# nrf9230_enga_sysctrl register map
Vendor: Nordic Semiconductor; Series: nRF92; File version: 1
Registers are 32-bit, read-write, reset 0x0 unless marked. A register's access mark holds for its fields unless they carry their own. Offsets are from the block's base; [hi:lo] are bit positions; lines under a group give offsets from that group; {n}, {i} and the like mark numbered series; 'fields as' and 'values as' point back to an identical list.

## ROMC — ROM Controller
Base 0x5F8C6000
0x500 POWER group — Unspecified
  0x00 CONTROL reset 0x1 — ROM power control register.
    [0] MEM0 — Keep the ROM block MEM[0] on or off when in System ON mode.
      0=Off (Power down); 1=On (Power up)

## MEMCONF120 — Memory configuration 0
Base 0x5F8C7000
Same registers: MEMCONF130 0x5F905000
{0x500+0x10*i} POWER[{i}] (i=0..1) group — Unspecified
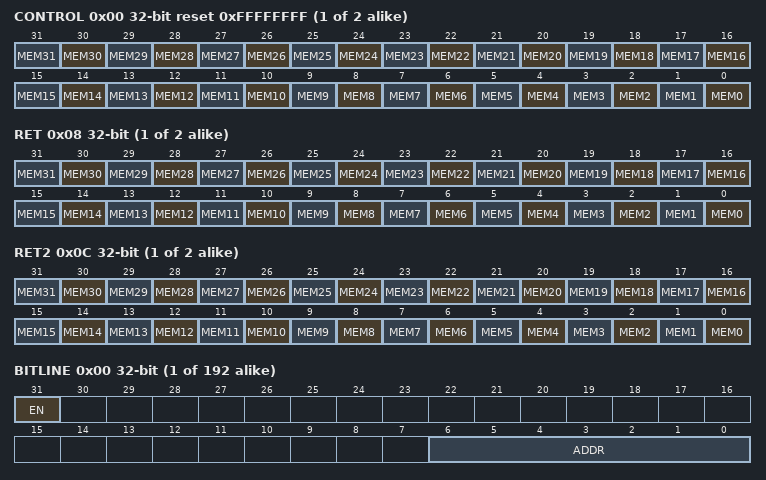
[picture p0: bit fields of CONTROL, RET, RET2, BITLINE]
  0x00 CONTROL reset 0xFFFFFFFF — Description cluster: Control memory block power.
    [all] fields
      0=Off (Power down); 1=On (Power up)
    [n] MEM{n} (n=0..31) — Keep the memory block MEM[{n}] on or off when in System ON mode.
  0x08 RET — Description cluster: RAM retention for RAM [n].
    [all] fields
      0=Off (Retention off); 1=On (Retention on)
    [n] MEM{n} (n=0..31) — Keep the RAM block MEM[{n}] retained when the parent power domain of the RAM is off.
  0x0C RET2 — Description cluster: RAM retention for the second bank in the RAM block
    [all] fields
      0=Off (Retention off); 1=On (Retention on)
    [n] MEM{n} (n=0..31) — Keep the second bank in RAM block MEM[{n}] retained when parent power domain of the RAM is off.
{0x600+4i} REPAIR[{i}] (i=0..191) group — Unspecified
  0x00 BITLINE — Description cluster: Repair configuration for RAM blocks.
    [31] EN — Enable bitline repair
      0=Disabled (Repair disabled.); 1=Enabled (Repair enabled.)
    [6:0] ADDR — Repair address of the bitline
{0x900+4i} BLOCKTYPE[{i}] (i=0..63) group — Unspecified
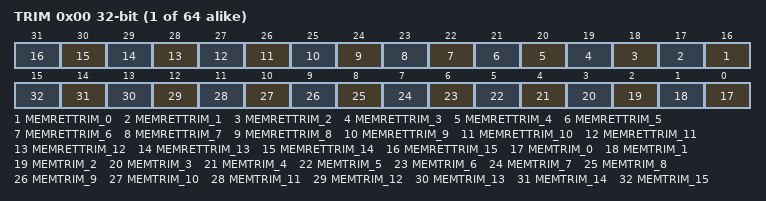
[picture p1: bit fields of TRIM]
  0x00 TRIM — Description cluster: Trim configuration for the memory block types.
    [n+16] MEMRETTRIM_{n} (n=0..15) — Trimming for retention mode for decreased leakage. Must be kept active in RAM retention mode.
    [n] MEMTRIM_{n} (n=0..15) — Read/write margin trim.

## GLOBAL_MUTEX120 — MUTEX 0
Base 0x4F8D2000
Same registers: GLOBAL_MUTEX130 0x4F927000
{0x400+4i} MUTEX[{i}] (i=0..31) — Description collection: Mutex register
  [0] MUTEX — Mutex register n
    0=Unlocked (Mutex n is in unlocked state); 1=Locked (Mutex n is in locked state)

## GLOBAL_PROTOTYPE — Prototype HW information registers.
Base 0x4F8D2000; alternate view of GLOBAL_MUTEX120
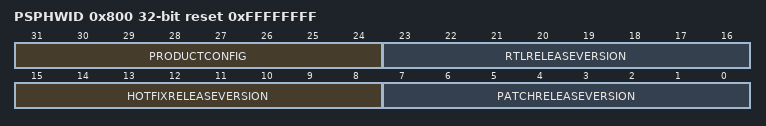
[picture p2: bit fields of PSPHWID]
0x800 PSPHWID ro reset 0xFFFFFFFF — PSP hardware ID register, unique ID for each prototype release. Used to identify RTL release that prototype is based on.
  [31:24] PRODUCTCONFIG
  [23:16] RTLRELEASEVERSION — First letter of RTL release version in ASCII corresponding to A-Z.
  [15:8] HOTFIXRELEASEVERSION
  [7:0] PATCHRELEASEVERSION — PSP patch/bugfix release version
0x804 FPGATIMESTAMP ro — 32-bit timestamp value stored by the FPGA bitstream in format ddddd_MMMM_yyyyyy_hhhhh_mmmmmm_ssssss. Unique for every FPGA netlist implementation, not dependent to RTL synthesis. 0x87654321 set in emulator database.
  [31:0] FPGATIMESTAMP — ddddd = 5 bits to represent 31 days in a month. MMMM = 4 bits to represent 12 months in a year. yyyyyy = 6 bits to represent 0 to 63 (to note year 2000 to 2063). hhhhh = 5 bits to represent 24 hours in a day. mmmmmm = 6 bits to represent 60 minutes in an hour. ssssss = 6 bits to represent 60 seconds in a minute.
0x808 EMULATORSPEEDVALUE ro — Used to store real speed of emulator is running. Used by SW to config UART speed etc, to ensure correct operation.
  [31:0] EMULATORSPEEDVALUE — Actual clock speed for FCLK 400M in emulator (Hz). In FPGA set to 0x0.
0x80C FPGACLOCKDIVIDERRATIO ro — Overall clock divider ratio for FPGA
  [31:0] FPGACLOCKDIVIDERRATIO — Overall clock divider ratio for FPGA. Set to 0 for emulator database.

## GLOBAL_I3C120 — I3C 0
Base 0x5F8D3000
Same registers: GLOBAL_I3C121 0x5F8DE000
0x100 EVENTS_CORE — Event indicating that interrupt triggered at I3C core
  [0] EVENTS_CORE
    0=NotGenerated (Event not generated); 1=Generated (Event generated)
0x104 EVENTS_DMA — Event indicating that interrupt triggered at I3C DMA
  [0] EVENTS_DMA
    values as EVENTS_CORE.EVENTS_CORE
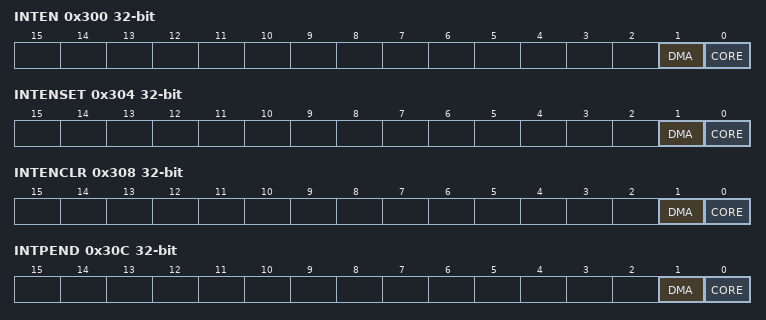
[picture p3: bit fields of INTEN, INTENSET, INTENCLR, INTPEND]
0x300 INTEN — Enable or disable interrupt
  [1] DMA — Enable or disable interrupt for event DMA
    0=Disabled; 1=Enabled
  [0] CORE — Enable or disable interrupt for event CORE
    0=Disabled; 1=Enabled
0x304 INTENSET — Enable interrupt
  [1] DMA — Write '1' to enable interrupt for event DMA
    on read: 0=Disabled (Read: Disabled); 1=Enabled (Read: Enabled) | on write: 1=Set (Enable)
  [0] CORE — Write '1' to enable interrupt for event CORE
    values as DMA
0x308 INTENCLR — Disable interrupt
  [1] DMA — Write '1' to disable interrupt for event DMA
    on read: 0=Disabled (Read: Disabled); 1=Enabled (Read: Enabled) | on write: 1=Clear (Disable)
  [0] CORE — Write '1' to disable interrupt for event CORE
    values as DMA
0x30C INTPEND ro — Pending interrupts
  [1] DMA — Read pending status of interrupt for event DMA
    on read: 0=NotPending (Read: Not pending); 1=Pending (Read: Pending)
  [0] CORE — Read pending status of interrupt for event CORE
    values as DMA
0x400 ENABLE — Enable I3C peripheral.
  [0] EN — Enable
    0=Disabled (I3C peripheral disabled.); 1=Enabled (I3C peripheral enabled.)
0x404 CDR group — Unspecified
  0x00 STARTOFFSET reset 0x4 — Start offset of recovered clock
    [15:0] VAL — Value
  0x04 MAXCYCLERATIO reset 0x1C — Maximum cycle ratio between SDA/SCL and CDR (clock and data recovery) clock
    [15:0] VAL — Value
  0x08 MAXSKEW reset 0x5 — Maximum skew between SCL and SCL in CDR clock cycles
    [7:0] VAL — Value
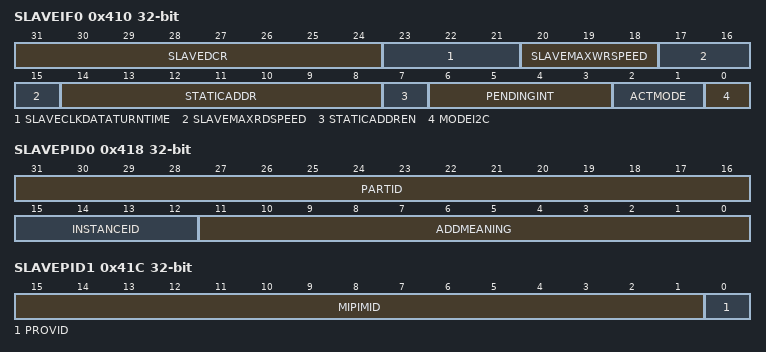
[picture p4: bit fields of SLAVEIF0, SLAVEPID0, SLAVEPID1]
0x410 SLAVEIF0 — I3C slave interface 0
  [31:24] SLAVEDCR — Device Characteristic Register value
  [23:21] SLAVECLKDATATURNTIME — Slave maximum clock data turnaround time
  [20:18] SLAVEMAXWRSPEED — Slave maximum write write rate
  [17:15] SLAVEMAXRDSPEED — Slave maximum read data rate
  [14:8] STATICADDR — Slave static address
  [7] STATICADDREN — Slave static address valid
    0=DISABLED (Unspecified); 1=ENABLED (Unspecified)
  [6:3] PENDINGINT — Pending interrupt information for GETSTATUS CCC
  [2:1] ACTMODE — Slave activity mode for GETSTATUS CCC
  [0] MODEI2C — I2C or I3C mode select signal
    0=DISABLED (Unspecified); 1=ENABLED (Unspecified)
0x414 SLAVEIF1 — I3C slave interface 1
  [0] WAKEUP ro — Slave wakeup signal
    0=DISABLED (Unspecified); 1=ENABLED (Unspecified)
0x418 SLAVEPID0 — Slave Device Provisioned ID 0
  [31:16] PARTID
  [15:12] INSTANCEID
  [11:0] ADDMEANING — Additional Meaning
0x41C SLAVEPID1 — Slave Device Provisioned ID 1
  [15:1] MIPIMID — MIPI Manufacturer ID
  [0] PROVID — Provisional ID Type Selector
0x420 KEEPSDA — Enable or disable the SDA high-keeper used for Master-to-Slave and Slave-to-Master bus hand-off.
  [0] ENABLE — Enable or disable the SDA high-keeper
    0=Disabled (High-keeper disabled.); 1=Enabled (High-keeper enabled.)
0x424 KEEPSCL — Enable or disable the SCL high-keeper used for Master-to-Slave and Slave-to-Master bus hand-off.
  [0] ENABLE — Enable or disable the SCL high-keeper
    values as KEEPSDA.ENABLE

## Notices in the file
Copyright (c) 2010 - 2023, Nordic Semiconductor ASA
All rights reserved.
Redistribution and use in source and binary forms, with or without modification,
are permitted provided that the following conditions are met:
1. Redistributions of source code must retain the above copyright notice, this
list of conditions and the following disclaimer.
2. Redistributions in binary form, except as embedded into a Nordic
Semiconductor ASA integrated circuit in a product or a software update for
such product, must reproduce the above copyright notice, this list of
conditions and the following disclaimer in the documentation and/or other
materials provided with the distribution.
3. Neither the name of Nordic Semiconductor ASA nor the names of its
contributors may be used to endorse or promote products derived from this
software without specific prior written permission.
4. This software, with or without modification, must only be used with a
Nordic Semiconductor ASA integrated circuit.
5. Any software provided in binary form under this license must not be reverse
engineered, decompiled, modified and/or disassembled.
THIS SOFTWARE IS PROVIDED BY NORDIC SEMICONDUCTOR ASA "AS IS" AND ANY EXPRESS
OR IMPLIED WARRANTIES, INCLUDING, BUT NOT LIMITED TO, THE IMPLIED WARRANTIES
OF MERCHANTABILITY, NONINFRINGEMENT, AND FITNESS FOR A PARTICULAR PURPOSE ARE
DISCLAIMED. IN NO EVENT SHALL NORDIC SEMICONDUCTOR ASA OR CONTRIBUTORS BE
LIABLE FOR ANY DIRECT, INDIRECT, INCIDENTAL, SPECIAL, EXEMPLARY, OR
CONSEQUENTIAL DAMAGES (INCLUDING, BUT NOT LIMITED TO, PROCUREMENT OF SUBSTITUTE
GOODS OR SERVICES; LOSS OF USE, DATA, OR PROFITS; OR BUSINESS INTERRUPTION)
HOWEVER CAUSED AND ON ANY THEORY OF LIABILITY, WHETHER IN CONTRACT, STRICT
LIABILITY, OR TORT (INCLUDING NEGLIGENCE OR OTHERWISE) ARISING IN ANY WAY OUT
OF THE USE OF THIS SOFTWARE, EVEN IF ADVISED OF THE POSSIBILITY OF SUCH DAMAGE.
